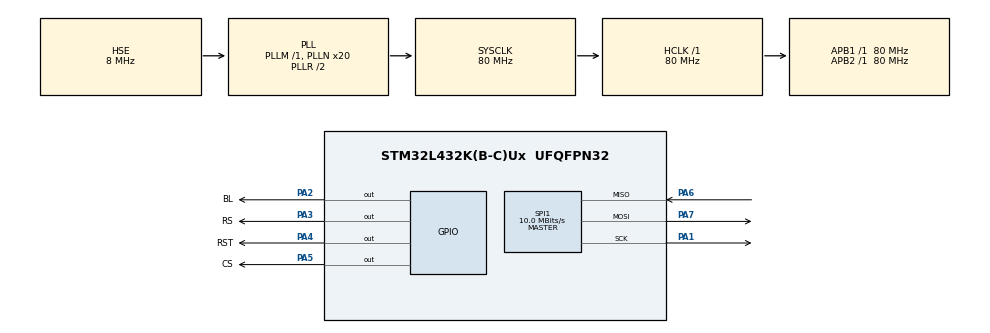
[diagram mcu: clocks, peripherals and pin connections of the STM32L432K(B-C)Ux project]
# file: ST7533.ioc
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Mcu.Family=STM32L4
Mcu.Name=STM32L432K(B-C)Ux
Mcu.Package=UFQFPN32
NVIC.PriorityGroup=NVIC_PRIORITYGROUP_4
PA0.Mode=HSE-External-Clock-Source-for-LittleOrca
PA0.Signal=RCC_CK_IN
PA1.Mode=Full_Duplex_Master
PA1.Signal=SPI1_SCK
PA13\ (JTMS-SWDIO).Mode=Serial_Wire
PA13\ (JTMS-SWDIO).Signal=SYS_JTMS-SWDIO
PA14\ (JTCK-SWCLK).Mode=Serial_Wire
PA14\ (JTCK-SWCLK).Signal=SYS_JTCK-SWCLK
PA2.GPIO_Label=BL
PA2.Signal=GPIO_Output
PA3.GPIO_Label=RS
PA3.Signal=GPIO_Output
PA4.GPIO_Label=RST
PA4.Signal=GPIO_Output
PA5.GPIO_Label=CS
PA5.Signal=GPIO_Output
PA6.Mode=Full_Duplex_Master
PA6.Signal=SPI1_MISO
PA7.Mode=Full_Duplex_Master
PA7.Signal=SPI1_MOSI
PC14-OSC32_IN\ (PC14).Mode=LSE-External-Clock-Source
PC14-OSC32_IN\ (PC14).Signal=RCC_OSC32_IN
ProjectManager.HeapSize=0x200
ProjectManager.StackSize=0x400
ProjectManager.TargetToolchain=MDK-ARM V5
RCC.ADCFreq_Value=32000000
RCC.AHBFreq_Value=80000000
RCC.APB1Freq_Value=80000000
RCC.APB1TimFreq_Value=80000000
RCC.APB2Freq_Value=80000000
RCC.APB2TimFreq_Value=80000000
RCC.CortexFreq_Value=80000000
RCC.HCLKFreq_Value=80000000
RCC.HSE_VALUE=8000000
RCC.HSI48_VALUE=48000000
RCC.HSI_VALUE=16000000
RCC.LSE_VALUE=32768
RCC.MSI_VALUE=4000000
RCC.PLLN=20
RCC.PLLSourceVirtual=RCC_PLLSOURCE_HSE
RCC.SYSCLKFreq_VALUE=80000000
RCC.SYSCLKSource=RCC_SYSCLKSOURCE_PLLCLK
RCC.USBFreq_Value=32000000
RCC.VCOOutputFreq_Value=160000000
SPI1.BaudRatePrescaler=SPI_BAUDRATEPRESCALER_8
SPI1.CLKPolarity=SPI_POLARITY_HIGH
SPI1.CalculateBaudRate=10.0 MBits/s
SPI1.DataSize=SPI_DATASIZE_8BIT
SPI1.Direction=SPI_DIRECTION_2LINES
SPI1.Mode=SPI_MODE_MASTER
SPI1.VirtualType=VM_MASTER
board=custom

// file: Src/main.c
/* USER CODE BEGIN Header */
/**
  ******************************************************************************
  * @file           : main.c
  * @brief          : Main program body
  ******************************************************************************
  * @attention
  *
  * <h2><center>&copy; Copyright (c) 2019 STMicroelectronics.
  * All rights reserved.</center></h2>
  *
  * This software component is licensed by ST under BSD 3-Clause license,
  * the "License"; You may not use this file except in compliance with the
  * License. You may obtain a copy of the License at:
  *                        opensource.org/licenses/BSD-3-Clause
  *
  ******************************************************************************
  */
/* USER CODE END Header */

#include "main.h"
#include "spi.h"
#include "gpio.h"

/* USER CODE BEGIN Includes */
#include "st7533.h"
/* USER CODE END Includes */

void SystemClock_Config(void);

int main(void)
{

  /* MCU Configuration--------------------------------------------------------*/

  /* Reset of all peripherals, Initializes the Flash interface and the Systick. */
  HAL_Init();

  /* Configure the system clock */
  SystemClock_Config();

  /* Initialize all configured peripherals */
  MX_GPIO_Init();
  MX_SPI1_Init();
  /* USER CODE BEGIN 2 */
	lcd7735_ini();
  /* USER CODE END 2 */
	int i;
  /* Infinite loop */
  while (1)
  {

    /* USER CODE BEGIN 3 */
		lcd7735_fillrect(0,0,128,160,GREEN);
		lcd7735_fillrect(0,0,128,160,YELLOW);
		lcd7735_fillrect(0,0,128,160,BLACK);
		for(i=0;i<128;i++)
			lcd7735_putpix(0,i,GREEN);
  }
  /* USER CODE END 3 */
}

void SystemClock_Config(void)
{
  RCC_OscInitTypeDef RCC_OscInitStruct = {0};
  RCC_ClkInitTypeDef RCC_ClkInitStruct = {0};

  /** Initializes the CPU, AHB and APB busses clocks
  */
  RCC_OscInitStruct.OscillatorType = RCC_OSCILLATORTYPE_HSE;
  RCC_OscInitStruct.HSEState = RCC_HSE_BYPASS;
  RCC_OscInitStruct.PLL.PLLState = RCC_PLL_ON;
  RCC_OscInitStruct.PLL.PLLSource = RCC_PLLSOURCE_HSE;
  RCC_OscInitStruct.PLL.PLLM = 1;
  RCC_OscInitStruct.PLL.PLLN = 20;
  RCC_OscInitStruct.PLL.PLLP = RCC_PLLP_DIV7;
  RCC_OscInitStruct.PLL.PLLQ = RCC_PLLQ_DIV2;
  RCC_OscInitStruct.PLL.PLLR = RCC_PLLR_DIV2;
  if (HAL_RCC_OscConfig(&RCC_OscInitStruct) != HAL_OK)
  {
    Error_Handler();
  }
  /** Initializes the CPU, AHB and APB busses clocks
  */
  RCC_ClkInitStruct.ClockType = RCC_CLOCKTYPE_HCLK|RCC_CLOCKTYPE_SYSCLK
                              |RCC_CLOCKTYPE_PCLK1|RCC_CLOCKTYPE_PCLK2;
  RCC_ClkInitStruct.SYSCLKSource = RCC_SYSCLKSOURCE_PLLCLK;
  RCC_ClkInitStruct.AHBCLKDivider = RCC_SYSCLK_DIV1;
  RCC_ClkInitStruct.APB1CLKDivider = RCC_HCLK_DIV1;
  RCC_ClkInitStruct.APB2CLKDivider = RCC_HCLK_DIV1;

  if (HAL_RCC_ClockConfig(&RCC_ClkInitStruct, FLASH_LATENCY_4) != HAL_OK)
  {
    Error_Handler();
  }
  /** Configure the main internal regulator output voltage
  */
  if (HAL_PWREx_ControlVoltageScaling(PWR_REGULATOR_VOLTAGE_SCALE1) != HAL_OK)
  {
    Error_Handler();
  }
}

void Error_Handler(void)
{
}

/************************ (C) COPYRIGHT STMicroelectronics *****END OF FILE****/
